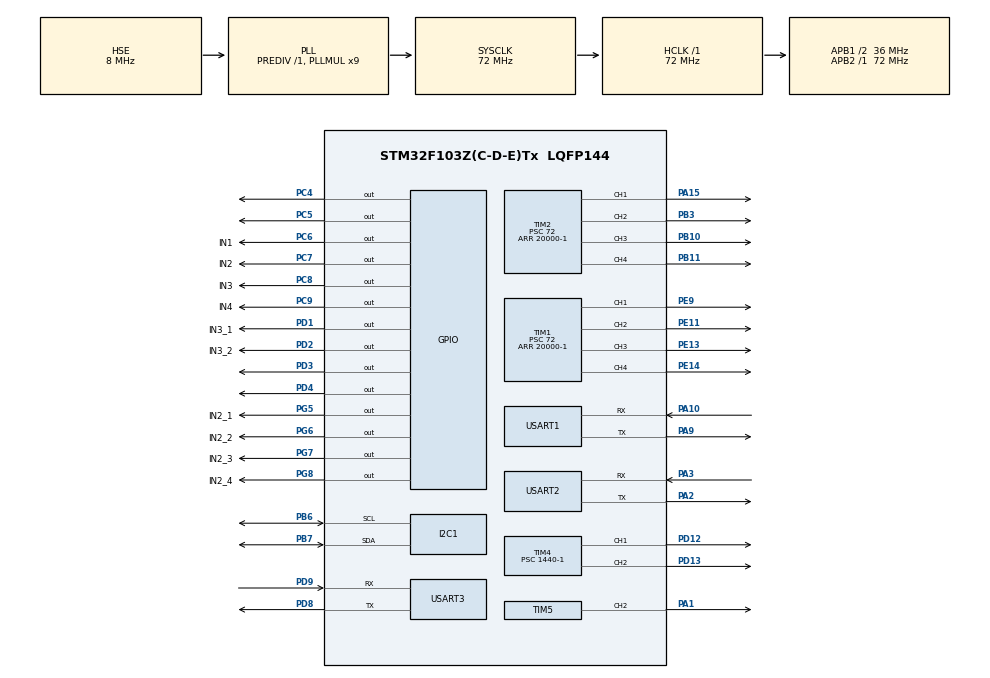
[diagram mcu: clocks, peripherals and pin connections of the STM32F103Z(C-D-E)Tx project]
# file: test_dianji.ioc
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Mcu.Family=STM32F1
Mcu.Name=STM32F103Z(C-D-E)Tx
Mcu.Package=LQFP144
NVIC.PriorityGroup=NVIC_PRIORITYGROUP_4
NVIC.TIM3_IRQn=true\:0\:0\:false\:false\:true\:true\:true\:true
NVIC.USART2_IRQn=true\:0\:0\:false\:false\:true\:true\:true\:true
OSC_IN.Mode=HSE-External-Oscillator
OSC_IN.Signal=RCC_OSC_IN
OSC_OUT.Mode=HSE-External-Oscillator
OSC_OUT.Signal=RCC_OSC_OUT
PA1.Signal=S_TIM5_CH2
PA10.Mode=Asynchronous
PA10.Signal=USART1_RX
PA13.Mode=Serial_Wire
PA13.Signal=SYS_JTMS-SWDIO
PA14.Mode=Serial_Wire
PA14.Signal=SYS_JTCK-SWCLK
PA15.Signal=S_TIM2_CH1_ETR
PA2.Mode=Asynchronous
PA2.Signal=USART2_TX
PA3.Mode=Asynchronous
PA3.Signal=USART2_RX
PA9.Mode=Asynchronous
PA9.Signal=USART1_TX
PB10.Signal=S_TIM2_CH3
PB11.Signal=S_TIM2_CH4
PB3.Signal=S_TIM2_CH2
PB6.Mode=I2C
PB6.Signal=I2C1_SCL
PB7.Mode=I2C
PB7.Signal=I2C1_SDA
PC14-OSC32_IN.Mode=LSE-External-Oscillator
PC14-OSC32_IN.Signal=RCC_OSC32_IN
PC15-OSC32_OUT.Mode=LSE-External-Oscillator
PC15-OSC32_OUT.Signal=RCC_OSC32_OUT
PC4.Signal=GPIO_Output
PC5.Signal=GPIO_Output
PC6.GPIO_Label=IN1
PC6.Signal=GPIO_Output
PC7.GPIO_Label=IN2
PC7.PinState=GPIO_PIN_SET
PC7.Signal=GPIO_Output
PC8.GPIO_Label=IN3
PC8.PinState=GPIO_PIN_SET
PC8.Signal=GPIO_Output
PC9.GPIO_Label=IN4
PC9.Signal=GPIO_Output
PD1.GPIO_Label=IN3_1
PD1.Signal=GPIO_Output
PD12.Signal=S_TIM4_CH1
PD13.Signal=S_TIM4_CH2
PD2.GPIO_Label=IN3_2
PD2.Signal=GPIO_Output
PD3.Signal=GPIO_Output
PD4.Signal=GPIO_Output
PD8.Mode=Asynchronous
PD8.Signal=USART3_TX
PD9.Mode=Asynchronous
PD9.Signal=USART3_RX
PE11.Signal=S_TIM1_CH2
PE13.Signal=S_TIM1_CH3
PE14.Signal=S_TIM1_CH4
PE9.Signal=S_TIM1_CH1
PG5.GPIO_Label=IN2_1
PG5.Signal=GPIO_Output
PG6.GPIO_Label=IN2_2
PG6.Signal=GPIO_Output
PG7.GPIO_Label=IN2_3
PG7.Signal=GPIO_Output
PG8.GPIO_Label=IN2_4
PG8.Signal=GPIO_Output
ProjectManager.HeapSize=0x200
ProjectManager.StackSize=0x400
ProjectManager.TargetToolchain=MDK-ARM V5.32
RCC.AHBFreq_Value=72000000
RCC.APB1CLKDivider=RCC_HCLK_DIV2
RCC.APB1Freq_Value=36000000
RCC.APB1TimFreq_Value=72000000
RCC.APB2Freq_Value=72000000
RCC.APB2TimFreq_Value=72000000
RCC.HCLKFreq_Value=72000000
RCC.PLLMUL=RCC_PLL_MUL9
RCC.PLLSourceVirtual=RCC_PLLSOURCE_HSE
RCC.SYSCLKFreq_VALUE=72000000
RCC.SYSCLKSource=RCC_SYSCLKSOURCE_PLLCLK
RCC.USBFreq_Value=72000000
SH.S_TIM1_CH1.0=TIM1_CH1,PWM Generation1 CH1
SH.S_TIM1_CH2.0=TIM1_CH2,PWM Generation2 CH2
SH.S_TIM1_CH3.0=TIM1_CH3,PWM Generation3 CH3
SH.S_TIM1_CH4.0=TIM1_CH4,PWM Generation4 CH4
SH.S_TIM2_CH1_ETR.0=TIM2_CH1,PWM Generation1 CH1
SH.S_TIM2_CH2.0=TIM2_CH2,PWM Generation2 CH2
SH.S_TIM2_CH3.0=TIM2_CH3,PWM Generation3 CH3
SH.S_TIM2_CH4.0=TIM2_CH4,PWM Generation4 CH4
SH.S_TIM4_CH1.0=TIM4_CH1,PWM Generation1 CH1
SH.S_TIM4_CH2.0=TIM4_CH2,PWM Generation2 CH2
SH.S_TIM5_CH2.0=TIM5_CH2,PWM Generation2 CH2
TIM1.Channel-PWM\ Generation1\ CH1=TIM_CHANNEL_1
TIM1.Channel-PWM\ Generation2\ CH2=TIM_CHANNEL_2
TIM1.Channel-PWM\ Generation3\ CH3=TIM_CHANNEL_3
TIM1.Channel-PWM\ Generation4\ CH4=TIM_CHANNEL_4
TIM1.Period=20000-1
TIM1.Prescaler=72
TIM1.Pulse-PWM\ Generation1\ CH1=500
TIM1.Pulse-PWM\ Generation2\ CH2=500
TIM1.Pulse-PWM\ Generation3\ CH3=500
TIM1.Pulse-PWM\ Generation4\ CH4=500
TIM2.Channel-PWM\ Generation1\ CH1=TIM_CHANNEL_1
TIM2.Channel-PWM\ Generation2\ CH2=TIM_CHANNEL_2
TIM2.Channel-PWM\ Generation3\ CH3=TIM_CHANNEL_3
TIM2.Channel-PWM\ Generation4\ CH4=TIM_CHANNEL_4
TIM2.Period=20000-1
TIM2.Prescaler=72
TIM2.Pulse-PWM\ Generation1\ CH1=500
TIM2.Pulse-PWM\ Generation2\ CH2=500
TIM3.Period=100
TIM3.Prescaler=7200-1
TIM4.Channel-PWM\ Generation1\ CH1=TIM_CHANNEL_1
TIM4.Channel-PWM\ Generation2\ CH2=TIM_CHANNEL_2
TIM4.Period=100
TIM4.Prescaler=1440-1
TIM4.Pulse-PWM\ Generation1\ CH1=50
TIM4.Pulse-PWM\ Generation2\ CH2=50
TIM5.Channel-PWM\ Generation2\ CH2=TIM_CHANNEL_2
TIM5.Period=10000
TIM5.Prescaler=72-1
USART1.VirtualMode=VM_ASYNC
USART2.VirtualMode=VM_ASYNC
USART3.VirtualMode=VM_ASYNC
VP_TIM3_VS_ClockSourceINT.Mode=Internal
board=custom

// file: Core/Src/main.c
/* USER CODE BEGIN Header */
/**
  ******************************************************************************
  * @file           : main.c
  * @brief          : Main program body
  ******************************************************************************
  * @attention
  *
  * Copyright (c) 2023 STMicroelectronics.
  * All rights reserved.
  *
  * This software is licensed under terms that can be found in the LICENSE file
  * in the root directory of this software component.
  * If no LICENSE file comes with this software, it is provided AS-IS.
  *
  ******************************************************************************
  */
/* USER CODE END Header */
#include "main.h"
#include "i2c.h"
#include "tim.h"
#include "usart.h"
#include "gpio.h"
#include "Motor.h"

/* USER CODE BEGIN Includes */
#include "MG996.h"
#include "L298N.h"

/* USER CODE END Includes */

void SystemClock_Config(void);

int main(void)
{

  /* MCU Configuration--------------------------------------------------------*/

  /* Reset of all peripherals, Initializes the Flash interface and the Systick. */
  HAL_Init();

  /* Configure the system clock */
  SystemClock_Config();

  /* Initialize all configured peripherals */
  MX_GPIO_Init();
  MX_TIM1_Init();
  MX_TIM2_Init();
  MX_I2C1_Init();
  MX_TIM5_Init();
  MX_TIM3_Init();
  MX_USART1_UART_Init();
  MX_USART2_UART_Init();
  MX_USART3_UART_Init();
  MX_TIM4_Init();
  /* USER CODE BEGIN 2 */

 	//�򿪶�ʱ��ͨ��
    HAL_TIM_PWM_Start(&htim1,TIM_CHANNEL_1);
	HAL_TIM_PWM_Start(&htim1,TIM_CHANNEL_2);
	HAL_TIM_PWM_Start(&htim1,TIM_CHANNEL_3);
	HAL_TIM_PWM_Start(&htim1,TIM_CHANNEL_4);
	HAL_TIM_PWM_Start(&htim2,TIM_CHANNEL_1);
	HAL_TIM_PWM_Start(&htim2,TIM_CHANNEL_2);
	HAL_TIM_PWM_Start(&htim4,TIM_CHANNEL_1);
	HAL_TIM_PWM_Start(&htim4,TIM_CHANNEL_2);

	//inital_mg();
	//HAL_Delay(1000);
	//main_program();
  /* USER CODE END 2 */

  /* Infinite loop */
  while (1)
  {

    /* USER CODE BEGIN 3 */

//    IN1();
   IN2();
//    IN3();
	 // main_program();

  }
  /* USER CODE END 3 */
}

void SystemClock_Config(void)
{
  RCC_OscInitTypeDef RCC_OscInitStruct = {0};
  RCC_ClkInitTypeDef RCC_ClkInitStruct = {0};

  /** Initializes the RCC Oscillators according to the specified parameters
  * in the RCC_OscInitTypeDef structure.
  */
  RCC_OscInitStruct.OscillatorType = RCC_OSCILLATORTYPE_HSE;
  RCC_OscInitStruct.HSEState = RCC_HSE_ON;
  RCC_OscInitStruct.HSEPredivValue = RCC_HSE_PREDIV_DIV1;
  RCC_OscInitStruct.HSIState = RCC_HSI_ON;
  RCC_OscInitStruct.PLL.PLLState = RCC_PLL_ON;
  RCC_OscInitStruct.PLL.PLLSource = RCC_PLLSOURCE_HSE;
  RCC_OscInitStruct.PLL.PLLMUL = RCC_PLL_MUL9;
  if (HAL_RCC_OscConfig(&RCC_OscInitStruct) != HAL_OK)
  {
    Error_Handler();
  }

  /** Initializes the CPU, AHB and APB buses clocks
  */
  RCC_ClkInitStruct.ClockType = RCC_CLOCKTYPE_HCLK|RCC_CLOCKTYPE_SYSCLK
                              |RCC_CLOCKTYPE_PCLK1|RCC_CLOCKTYPE_PCLK2;
  RCC_ClkInitStruct.SYSCLKSource = RCC_SYSCLKSOURCE_PLLCLK;
  RCC_ClkInitStruct.AHBCLKDivider = RCC_SYSCLK_DIV1;
  RCC_ClkInitStruct.APB1CLKDivider = RCC_HCLK_DIV2;
  RCC_ClkInitStruct.APB2CLKDivider = RCC_HCLK_DIV1;

  if (HAL_RCC_ClockConfig(&RCC_ClkInitStruct, FLASH_LATENCY_2) != HAL_OK)
  {
    Error_Handler();
  }
}

void Error_Handler(void)
{
  __disable_irq();
  while (1)
  {
  }
}
